# CONTROLSS_ECAP5_CONTROLSS_ECAP5 register map
Vendor: Texas Instruments
Peripheral module from a debugger description file (folder AM263).
Registers are 32-bit, read-write, reset 0x0 unless marked. A register's access mark holds for its fields unless they carry their own. Offsets are as the file gives them; lines under a group give offsets from that group; [hi:lo] are bit positions; {n}, {i} and the like mark numbered series; 'fields as' and 'values as' point back to an identical list; <NAME> marks a mode.

## CONTROLSS_ECAP5_CONTROLSS_ECAP5
0x00 CONTROLSS_ECAP5_TSCTR
  [31:0] TSCTR — Active 32-bit counter register that is used as the capture time-base HR mode : 1) This register reads HRCOUNTER value and is not writable 2) can be reset using CTRFILTRESET 3) Its not synchronized to SYSCLK domain so reads may not be accurate
0x04 CONTROLSS_ECAP5_CTRPHS
  [31:0] CTRPHS — Counter phase value register that can be programmed for phase lag/lead. This register CTRPHS is loaded into TSCTR upon either a SYNCI event or S/W force via a control bit. Used to achieve phase control synchronization with respect to other eCAP and EPWM time-bases. This register is not applicable in HR mode.
0x08 CONTROLSS_ECAP5_CAP1
  [31:0] CAP1 — This register can be loaded (written) by: - Time-Stamp counter value (TSCTR) during a capture event - Software - may be useful for test purposes or initialization - ARPD shadow register (CAP3) when used in APWM mode
0x0C CONTROLSS_ECAP5_CAP2
  [31:0] CAP2 — This register can be loaded (written) by: - Time-Stamp ( counter value) during a capture event - Software - may be useful for test purposes - ACMP shadow register (CAP4) when used in APWM mode
0x10 CONTROLSS_ECAP5_CAP3
  [31:0] CAP3 — In CMP mode, this is a time-stamp capture register. In APWM mode, this is the period shadow (APRD) register. You can update the PWM period value through this register. CAP3 (APRD) shadows CAP1 in this mode.
0x14 CONTROLSS_ECAP5_CAP4
  [31:0] CAP4 — In CMP mode, this is a time-stamp capture register. In APWM mode, this is the compare shadow (ACMP) register. You can update the PWM compare value via this register. CAP4 (ACMP) shadows CAP2 in this mode.
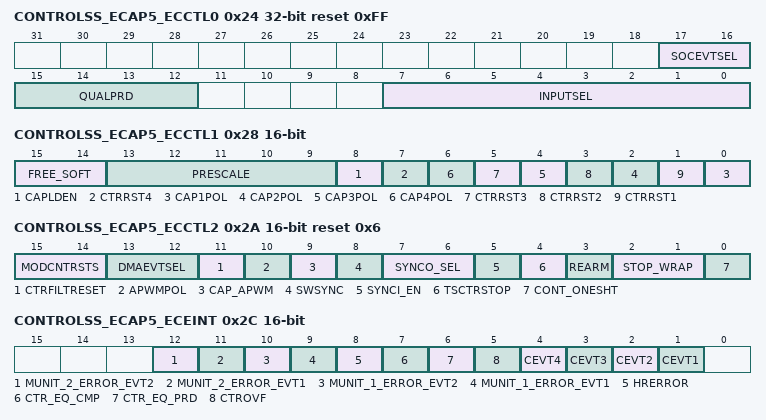
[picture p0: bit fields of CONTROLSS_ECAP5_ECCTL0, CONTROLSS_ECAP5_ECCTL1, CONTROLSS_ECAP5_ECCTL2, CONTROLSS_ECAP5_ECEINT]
0x24 CONTROLSS_ECAP5_ECCTL0 reset 0xFF
  [17:16] SOCEVTSEL — ADC SOC event select Capture Mode: 00b (R/W) = SOC trigger source is CEVT1 01b (R/W) = SOC trigger source is CEVT2 10b (R/W) = SOC trigger source is CEVT3 11b (R/W) = SOC trigger source is CEVT4 APWM Mode: 00b (R/W) = SOC trigger interrupt source is period match 01b (R/W) = SOC trigger interrupt source is compare match 10b (R/W) = SOC trigger interrupt source is period match or compare match 11b (R/W) = Disabled
  [15:12] QUALPRD — Qual period to filter out noise on input signals being monitored, Not applicable for HR mode. 0x0 : Bypass 0x1 : pulses of with 1 cycle or less will be filtered out 0x2 : pulses of with 2 cycles or less will be filtered out .... 0xF : pulses of with 15 cycles or less will be filtered out
  [7:0] INPUTSEL — Capture input source select bits 0x0 capture input is ECAPxINPUT[0] 0x1 capture input is ECAPxINPUT[1] 0x2 capture input is ECAPxINPUT[2] ... 0xFF capture input is ECAPxINPUT[256]
0x28 CONTROLSS_ECAP5_ECCTL1 16-bit
  [15:14] FREE_SOFT — Emulation Control 0x0 | ECAP_STOP_EMUTSCTR counter stops immediately on emulation suspend 0x1 | ECAP_RUNS_UNTILTSCTR counter runs until = 0 0x2 | ECAP_UNAF_EMU_SUSTSCTR counter is unaffected by emulation suspend (Run Free) 0x3 | ECAP_UNAF_EMU_SUS2TSCTR counter is unaffected by emulation suspend (Run Free)
  [13:9] PRESCALE — Event Filter prescale select 0x00 | ECAP_DIV1Divide by 1 (i.e,. no prescale, by-pass the prescaler) 0x01 | ECAP_DIV2Divide by 2 0x02 | ECAP_DIV4Divide by 4 0x03 | ECAP_DIV6Divide by 6 0x04 | ECAP_DIV8Divide by 8 0x05 | ECAP_DIV10Divide by 10 0x1E | ECAP_DIV60Divide by 60 0x1F | ECAP_DIV62Divide by 62
  [8] CAPLDEN — Enable Loading of CAP1-4 registers on a capture event. Note that this bit does not disable CEVTn events from being generated. 0 | ECAP_DISABLEDisable CAP1-4 register loads at capture event time. 1 | ECAP_ENABLEEnable CAP1-4 register loads at capture event time.
  [7] CTRRST4 — Counter Reset on Capture Event 4 0 | ECAP_DO_NOT_RESET_EVENT4Do not reset counter on Capture Event 4 (absolute time stamp operation) 1 | ECAP_RESET_EVENT4Reset counter after Capture Event 4 time-stamp has been captured (used in difference mode operation)
  [2n-2] CAP{n}POL (n=1..4) — Capture Event {n} Polarity select 0 | ECAP_CAP_EVENT{n}_RISECapture Event {n} triggered on a rising edge (RE) 1 | ECAP_CAP_EVENT{n}_FALLCapture Event {n} triggered on a falling edge (FE)
  [5] CTRRST3 — Counter Reset on Capture Event 3 0 | ECAP_DO_NOT_RESET_EVENT3Do not reset counter on Capture Event 3 (absolute time stamp) 1 | ECAP_RESET_EVENT3Reset counter after Event 3 time-stamp has been captured (used in difference mode operation)
  [3] CTRRST2 — Counter Reset on Capture Event 2 0 | ECAP_DO_NOT_RESET_EVENT2Do not reset counter on Capture Event 2 (absolute time stamp) 1 | ECAP_RESET_EVENT2Reset counter after Event 2 time-stamp has been captured (used in difference mode operation)
  [1] CTRRST1 — Counter Reset on Capture Event 1 0 | ECAP_DO_NOT_RESET_EVENT1Do not reset counter on Capture Event 1 (absolute time stamp) 1 | ECAP_RESET_EVENT1Reset counter after Event 1 time-stamp has been captured (used in difference mode operation)
0x2A CONTROLSS_ECAP5_ECCTL2 16-bit access not given reset 0x6
  [15:14] MODCNTRSTS rw — This bit field reads current status on modulo counter 00b (R) = CAP1 register gets loaded on next capture event. 01b (R) = CAP2 register gets loaded on next capture event. 10b (R) = CAP3 register gets loaded on next capture event. 11b (R) = CAP4 register gets loaded on next capture event.
  [13:12] DMAEVTSEL rw — DMA event select Capture Mode: 00b (R/W) = DMA interrupt source is CEVT1 01b (R/W) = DMA interrupt source is CEVT2 10b (R/W) = DMA interrupt source is CEVT3 11b (R/W) = DMA interrupt source is CEVT4 APWM Mode: 00b (R/W) = DMA interrupt source is period match 01b (R/W) = DMA interrupt source is compare match 10b (R/W) = DMA interrupt source is period match or compare match 11b (R/W) = Disabled
  [11] CTRFILTRESET — Reset Bit 0h (R) = No effect 1h (W) = Resets event filter, counter, modulo counter and CEVT[1,2,3,4] and CNTOVF , HRERROR flags Note: This provides an ability start capture module from known state in case spurious inputs are captured while ECAP is configured. (access RW RRETURNS0S)
  [10] APWMPOL rw — APWM output polarity select. This is applicable only in APWM operating mode. 0 | ECAP_OUTPUT_ACTIVE_HIGHOutput is active high (Compare value defines high time) 1 | ECAP_OUTPUT_ACTIVE_LOWOutput is active low (Compare value defines low time)
  [9] CAP_APWM rw — CAP/APWM operating mode select 0 | ECAP_MODULEECAP module operates in capture mode. This mode forces the following configuration: - Inhibits TSCTR resets via CTR = PRD event - Inhibits shadow loads on CAP1 and 2 registers - Permits user to enable CAP1-4 register load - CAPx/APWMx pin operates as a capture input 1 | ECAP_MODULE_APWMECAP module operates in APWM mode. This mode forces the following configuration: - Resets TSCTR on CTR = PRD event (period boundary - Permits shadow loading on CAP1 and 2 registers - Disables loading of time-stamps into CAP1-4 registers - CAPx/APWMx pin operates as a APWM output
  [8] SWSYNC — Software-forced Counter (TSCTR) Synchronizer. This provides the user a method to generate a synchronization pulse through software. In APWM mode, the synchronization pulse can also be sourced from the CTR = PRD event. 0 | ECAP_ZERO_NOEFFECTWriting a zero has no effect. Reading always returns a zero 1 | ECAP_WRITE_TSCTRWriting a one forces a TSCTR shadow load of current ECAP module and any ECAP modules down-stream providing the SYNCO_SEL bits are 0,0. After writing a 1, this bit returns to a zero. Note: Selection CTR = PRD is meaningful only in APWM mode; however, you can choose it in CAP mode if you find doing so useful. (access RW RRETURNS0S)
  [7:6] SYNCO_SEL rw — Sync-Out Select 0x0 | SWSYNCsync out signal is SWSYNC 0x1 | ECAP_CTR_PRD_TO_SYNCOUTSelect CTR = PRD event to be the sync-out signal 0x2 | ECAP_DISABLE_SYNC_OUTDisable sync out signal 0x3 | ECAP_DISABLE_SYNC_OUTDisable sync out signal
  [5] SYNCI_EN rw — Counter (TSCTR) Sync-In select mode 0 | ECAP_DISABLE_SYNC_INDisable sync-in option 1 | ECAP_ENABLE_COUNTER_REGISTEREnable counter (TSCTR) to be loaded from CTRPHS register upon either a SYNCI signal or a S/W force event.
  [4] TSCTRSTOP rw — Time Stamp (TSCTR) Counter Stop (freeze) Control 0 | ECAP_TSCTR_STOPPEDTSCTR stopped 1 | ECAP_TSCTR_FREE_RUNNINGTSCTR free-running
  [3] REARM — Re-Arming Control. Note: The re-arm function is valid in one shot or continuous mode 0 | ECAP_NO_EFFECT_RETURNS_0Has no effect (reading always returns a 0) 1 | ECAP_ARMS_ONESHOTArms the one-shot sequence as follows: 1) Resets the Mod4 counter to zero 2) Unfreezes the Mod4 counter 3) Enables capture register loads (access RW RRETURNS0S)
  [2:1] STOP_WRAP rw — Stop value for one-shot mode. This is the number (between 1-4) of captures allowed to occur before the CAP(1-4) registers are frozen, that is, capture sequence is stopped. Wrap value for continuous mode. This is the number (between 1-4) of the capture register in which the circular buffer wraps around and starts again. Notes: STOP_WRAP is compared to Mod4 counter and, when equal, 2 actions occur: - Mod4 counter is stopped (frozen) - Capture register loads are inhibited In one-shot mode, further interrupt events are blocked until re-armed. 0x0 | ECAP_STOPEVENT1_WRAPEVENT2Stop after Capture Event 1 in one-shot mode Wrap after Capture Event 1 in continuous mode. 0x1 | ECAP_STOPEVENT2_WRAPEVENT2Stop after Capture Event 2 in one-shot mode Wrap after Capture Event 2 in continuous mode. 0x2 | ECAP_STOPEVENT3_WRAPEVENT2Stop after Capture Event 3 in one-shot mode Wrap after Capture Event 3 in continuous mode. 0x3 | ECAP_STOPEVENT4_WRAPEVENT2Stop after Capture Event 4 in one-shot mode Wrap after Capture Event 4 in continuous mode.
  [0] CONT_ONESHT rw — Continuous or one-shot mode control (applicable only in capture mode) 0 | ECAP_OPP_CONTOperate in continuous mode 1 | ECAP_OPP_ONEOperate in one-Shot mode
0x2C CONTROLSS_ECAP5_ECEINT 16-bit
  [12] MUNIT_2_ERROR_EVT2 — Monitoring unit 2 error event 2 interrupt enable 0 : Disable Monitoring unit 2 error event 2 interrupt 1 : Enable Monitoring unit 2 error event 2 interrupt
  [11] MUNIT_2_ERROR_EVT1 — Monitoring unit 2 error event 2 interrupt enable 0 : Disable Monitoring unit 2 error event 1 interrupt 1 : Enable Monitoring unit 2 error event 1 interrupt
  [10] MUNIT_1_ERROR_EVT2 — Monitoring unit 1 error event 1 interrupt enable 0 : Disable Monitoring unit 1 error event 2 interrupt 1 : Enable Monitoring unit 1 error event 2 interrupt
  [9] MUNIT_1_ERROR_EVT1 — Monitoring unit 1 error event 1 interrupt enable 0 : Disable Monitoring unit 1 error event 1 interrupt 1 : Enable Monitoring unit 1 error event 1 interrupt
  [8] HRERROR — High resolution error interrupt enable 0 | ECAP_DISAB_HRERROR_INTERRUPTDisable High Resolution Error as an Interrupt source 1 | ECAP_ENAB_HRERROR_INTERRUPTEnable High Resolution Error as an Interrupt source
  [7] CTR_EQ_CMP — Counter Equal Compare Interrupt Enable 0 | ECAP_DISAB_CE_INTERRUPTDisable Compare Equal as an Interrupt source 1 | ECAP_ENAB_CE_INTERRUPTEnable Compare Equal as an Interrupt source
  [6] CTR_EQ_PRD — Counter Equal Period Interrupt Enable 0 | ECAP_DISAB_PE_INTERRUPTDisable Period Equal as an Interrupt source 1 | ECAP_ENAB_PE_INTERRUPTEnable Period Equal as an Interrupt source
  [5] CTROVF — Counter Overflow Interrupt Enable 0 | ECAP_DISAB_CO_INTERRUPTDisabled counter Overflow as an Interrupt source 1 | ECAP_ENAB_CO_INTERRUPTEnable counter Overflow as an Interrupt source
  [4] CEVT4 — Capture Event 4 Interrupt Enable 0 | ECAP_DISAB_CAP4_INTERRUPTDisable Capture Event 4 as an Interrupt source 1 | ECAP_ENAB_CAP4_INTERRUPTCapture Event 4 Interrupt Enable
  [3] CEVT3 — Capture Event 3 Interrupt Enable 0 | ECAP_DISAB_CAP3_INTERRUPTDisable Capture Event 3 as an Interrupt source 1 | ECAP_ENAB_CAP3_INTERRUPTEnable Capture Event 3 as an Interrupt source
  [2] CEVT2 — Capture Event 2 Interrupt Enable 0 | ECAP_DISAB_CAP2_INTERRUPTDisable Capture Event 2 as an Interrupt source 1 | ECAP_ENAB_CAP2_INTERRUPTEnable Capture Event 2 as an Interrupt source
  [1] CEVT1 — Capture Event 1 Interrupt Enable 0 | ECAP_DISAB_CAP1_INTERRUPTDisable Capture Event 1 as an Interrupt source 1 | ECAP_ENAB_CAP1_INTERRUPTEnable Capture Event 1 as an Interrupt source
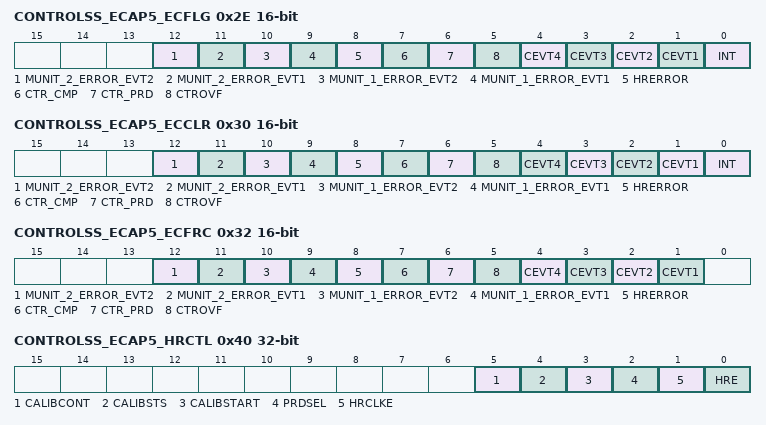
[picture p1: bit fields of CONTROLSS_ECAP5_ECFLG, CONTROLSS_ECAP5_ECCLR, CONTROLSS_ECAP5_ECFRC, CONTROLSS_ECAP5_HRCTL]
0x2E CONTROLSS_ECAP5_ECFLG 16-bit ro
  [12] MUNIT_2_ERROR_EVT2 — Error event 2 Interrupt Flag from monitoring unit 2
  [11] MUNIT_2_ERROR_EVT1 — Error event 2 Interrupt Flag from monitoring unit 2
  [10] MUNIT_1_ERROR_EVT2 — Error event 2 Interrupt Flag from monitoring unit 1
  [9] MUNIT_1_ERROR_EVT1 — Error event 2 Interrupt Flag from monitoring unit 1
  [8] HRERROR — High resolution error status flag Read0 | ECAP_INDICATE_NO_EVENTIndicates no event occurred Read1 | ECAP_INDICATE_HIGH_RESOLUTION_ERRORIndicates the High resolution Error occurred
  [7] CTR_CMP — Compare Equal Compare Status Flag. This flag is active only in APWM mode. Read0 | ECAP_INDICATE_NO_EVENTIndicates no event occurred Read1 | ECAP_INDICATE_COUNTER_COMPARE_REGIndicates the counter (TSCTR) reached the compare register value (ACMP)
  [6] CTR_PRD — Counter Equal Period Status Flag. This flag is only active in APWM mode. Read0 | ECAP_INDICATE_NO_EVENTIndicates no event occurred Read1 | ECAP_INDICATE_PERIOD_VALUE_RESETIndicates the counter (TSCTR) reached the period register value (APRD) and was reset.
  [5] CTROVF — Counter Overflow Status Flag. This flag is active in CAP and APWM mode. Read0 | ECAP_INDICATE_NO_EVENTIndicates no event occurred Read1 | ECAP_INDICATE_COUNTER_TRANSIndicates the counter (TSCTR) has made the transition from FFFFFFFF to 00000000
  [4] CEVT4 — Capture Event 4 Status Flag This flag is only active in CAP mode. Read0 | ECAP_INDICATE_NO_EVENTIndicates no event occurred Read1 | ECAP_INDICATE_4TH_EVENT_ECAPXIndicates the fourth event occurred at ECAPx pin
  [3] CEVT3 — Capture Event 3 Status Flag. This flag is active only in CAP mode. Read0 | ECAP_INDICATE_NO_EVENTIndicates no event occurred Read1 | ECAP_INDICATE_3RD_EVENT_ECAPXIndicates the third event occurred at ECAPx pin.
  [2] CEVT2 — Capture Event 2 Status Flag. This flag is only active in CAP mode. Read0 | ECAP_INDICATE_NO_EVENTIndicates no event occurred Read1 | ECAP_INDICATE_2ND_EVENT_ECAPXIndicates the second event occurred at ECAPx pin.
  [1] CEVT1 — Capture Event 1 Status Flag. This flag is only active in CAP mode. Read0 | ECAP_INDICATE_NO_EVENTIndicates no event occurred Read1 | ECAP_INDICATE_1ST_EVENT_ECAPXIndicates the first event occurred at ECAPx pin.
  [0] INT — Global Interrupt Status Flag Read0 | ECAP_INDICATE_NO_EVENTIndicates no event occurred Read1 | ECAP_INDICATE_INTERRUPTIndicates that an interrupt was generated.
0x30 CONTROLSS_ECAP5_ECCLR 16-bit access not given
  [12] MUNIT_2_ERROR_EVT2 — Writing '1' clears MUNIT_2_ERROR_EVT2 interrupt flag (access RW RRETURNS0S)
  [11] MUNIT_2_ERROR_EVT1 — Writing '1' clears MUNIT_2_ERROR_EVT1 interrupt flag (access RW RRETURNS0S)
  [10] MUNIT_1_ERROR_EVT2 — Writing '1' clears MUNIT_1_ERROR_EVT2 interrupt flag (access RW RRETURNS0S)
  [9] MUNIT_1_ERROR_EVT1 — Writing '1' clears MUNIT_1_ERROR_EVT1 interrupt flag (access RW RRETURNS0S)
  [8] HRERROR — High resolution error status Clear 0 | ECAP_0_NO_EFFECTWriting a 0 has no effect. Always reads back a 0 1 | ECAP_1_CLEARS_HRERRORWriting a 1 clears the HRERROR flag. (access RW RRETURNS0S)
  [7] CTR_CMP — Counter Equal Compare Status Clear 0 | ECAP_0_NO_EFFECTWriting a 0 has no effect. Always reads back a 0 1 | ECAP_1_CLEARS_CTR_CMPWriting a 1 clears the CTR=CMP flag. (access RW RRETURNS0S)
  [6] CTR_PRD — Counter Equal Period Status Clear 0 | ECAP_0_NO_EFFECTWriting a 0 has no effect. Always reads back a 0 1 | ECAP_1_CLEARS_CTR_PRDWriting a 1 clears the CTR=PRD flag. (access RW RRETURNS0S)
  [5] CTROVF — Counter Overflow Status Clear 0 | ECAP_0_NO_EFFECTWriting a 0 has no effect. Always reads back a 0 1 | ECAP_1_CLEARS_CTROVFWriting a 1 clears the CTROVF flag. (access RW RRETURNS0S)
  [n] CEVT{n} (n=1..4) — Capture Event {n} Status Clear 0 | ECAP_0_NO_EFFECTWriting a 0 has no effect. Always reads back a 0 1 | ECAP_1_CLEARS_CEVT{n}Writing a 1 clears the CEVT{n} flag. (access RW RRETURNS0S)
  [0] INT — ECAP Global Interrupt Status Clear 0 | ECAP_0_NO_EFFECTWriting a 0 has no effect. Always reads back a 0 1 | ECAP_1_CLEARS_INTWriting a 1 clears the INT flag and enable further interrupts to be generated if any of the event flags are set to 1 (access RW RRETURNS0S)
0x32 CONTROLSS_ECAP5_ECFRC 16-bit access not given
  [12] MUNIT_2_ERROR_EVT2 — Writing '1' sets MUNIT_2_ERROR_EVT2 interrupt flag (access RW RRETURNS0S)
  [11] MUNIT_2_ERROR_EVT1 — Writing '1' sets MUNIT_2_ERROR_EVT1 interrupt flag (access RW RRETURNS0S)
  [10] MUNIT_1_ERROR_EVT2 — Writing '1' sets MUNIT_1_ERROR_EVT2 interrupt flag (access RW RRETURNS0S)
  [9] MUNIT_1_ERROR_EVT1 — Writing '1' sets MUNIT_1_ERROR_EVT1 interrupt flag (access RW RRETURNS0S)
  [8] HRERROR — High resolution error Force interrupt 0 | ECAP_NO_EFFECT_0No effect. Always reads back a 0. 1 | ECAP_1_SETS_CTR_CMPWriting a 1 sets the CTR_CMP flag. (access RW RRETURNS0S)
  [7] CTR_CMP — Force Counter Equal Compare Interrupt. This event is only active in APWM mode. 0 | ECAP_NO_EFFECT_0No effect. Always reads back a 0. 1 | ECAP_1_SETS_CTR_CMPWriting a 1 sets the CTR_CMP flag. (access RW RRETURNS0S)
  [6] CTR_PRD — Force Counter Equal Period Interrupt. This event is only active in APWM mode. 0 | ECAP_NO_EFFECT_0No effect. Always reads back a 0. 1 | ECAP_1_CLEARS_CTR_PRDWriting a 1 sets the CTR_PRD flag. (access RW RRETURNS0S)
  [5] CTROVF — Force Counter Overflow 0 | ECAP_NO_EFFECT_0No effect. Always reads back a 0. 1 | ECAP_1_SETS_CTROVFWriting a 1 to this bit sets the CTROVF flag. (access RW RRETURNS0S)
  [4] CEVT4 — Force Capture Event 4. This event is only active in CAP mode. 0 | ECAP_NO_EFFECT_0No effect. Always reads back a 0. 1 | ECAP_1_SETS_CEVT4Writing a 1 sets the CEVT4 flag. (access RW RRETURNS0S)
  [3] CEVT3 — Force Capture Event 3. This event is only active in CAP mode. 0 | ECAP_NO_EFFECT_0No effect. Always reads back a 0. 1 | ECAP_1_SETS_CEVT3Writing a 1 sets the CEVT3 flag. (access RW RRETURNS0S)
  [2] CEVT2 — Force Capture Event 2. This event is only active in CAP mode. 0 | ECAP_NO_EFFECT_0No effect. Always reads back a 0. 1 | ECAP_1_SETS_CEVT2Writing a 1 sets the CEVT2 flag. (access RW RRETURNS0S)
  [1] CEVT1 — Force Capture Event 1. This event is only active in CAP mode. 0 | ECAP_NO_EFFECT_0No effect. Always reads back a 0. 1 | ECAP_1_SETS_CEVT1Sets the CEVT1 flag. (access RW RRETURNS0S)
0x3C CONTROLSS_ECAP5_ECAPSYNCINSEL reset 0x1
  [6:0] SEL — These bits determines the source of SYNCIN signal. 0x0 : Disabled using SOC tieoff. 0x7F : Refer to SOC spec for details.
0x40 CONTROLSS_ECAP5_HRCTL access not given
  [5] CALIBCONT rw — Continuous mode Calibration Select Bit: 0 Continuous mode disabled. 1 Continuous mode enabled. Calibration automatically restarts at end of current calibration cycle.
  [4] CALIBSTS ro — Calibration status Bit: 0 No active calibration cycle 1 Calibration cycle in progress
  [3] CALIBSTART — Calibration start Bit: 0 No effect 1 Starts the calibration cycle (access RW RRETURNS0S)
  [2] PRDSEL rw — Calibration Period Match Select Bit: 0 Use SYSCLK Counter For Period Match (default at reset) 1 Reserved
  [1] HRCLKE rw — High Resolution Clock Enable Bit: 0 High resolution clock disabled (default at reset) 1 High resolution clock enabled. The clock should be enabled before enabling the high res function via the HRE bit.
  [0] HRE rw — High Resolution Enable Bit: 0 High resolution mode disabled (default at reset) 1 High resolution mode enabled. Enabling this mode will connect the capture registers and edge event modes of the ECAP to be accessed by the High Res function. Note: The High Res clock needs to be enabled (using the HRCLKE bit) first before enabling the module. Allow a certain start up stabilization period before enabling the module.
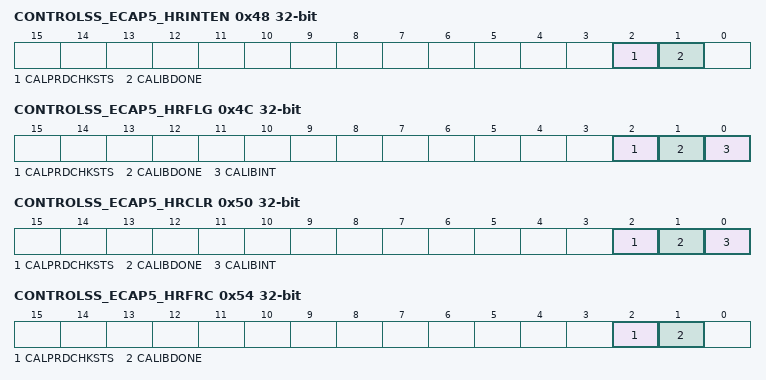
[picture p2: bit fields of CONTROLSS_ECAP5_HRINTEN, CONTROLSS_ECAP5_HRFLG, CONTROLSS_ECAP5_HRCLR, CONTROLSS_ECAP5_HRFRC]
0x48 CONTROLSS_ECAP5_HRINTEN
  [2] CALPRDCHKSTS — Calibration Period Check status Interrupt Enable: 0 Disable Calibration Period Check interrupt status 1 Enable Calibration Period Check interrupt status
  [1] CALIBDONE — Calibration done Interrupt Enable: 0 Disable Calibration done Interrupt 1 Enable Calibration done Interrupt
0x4C CONTROLSS_ECAP5_HRFLG ro
  [2] CALPRDCHKSTS — Calibration period check status Flag Bit: 1 Indicates that calibration ended before PRDCHK due to overflow on one of the counters. 0 Indicates no event occurred. Note: This bit remains latched until cleared by the user using the HRCLR [CALPRDCHKSTS] bit.
  [1] CALIBDONE — Calibration Done Interrupt Flag Bit: 1 Indicates calibration cycle is completed 0 Indicates calibration cycle has not completed. Note: This bit remains latched until cleared by the user using the HRCLR [CALIBDONE] bit.
  [0] CALIBINT — Global calibration Interrupt Status Flag: 1 Indicates that an interrupt was generated from CALIBDONE or CALPRDCHKSTS. 0 Indicates no interrupt generated.
0x50 CONTROLSS_ECAP5_HRCLR access not given
  [2] CALPRDCHKSTS — Clear Calibration period check status Flag Bit: 1 Clears the CALPRDCHKSTS flag register bit. 0 No effect. Note: H/W has priority over CPU writes if the user tries to clear a flag bit and an event occurs on the same cycle that tries to set the flag for the selected bit. (access RW RRETURNS0S)
  [1] CALIBDONE — Clear Calibration Done Interrupt Flag Bit: 1 Clears the CALIBDONE interrupt flag register bit. 0 No effect. Note: H/W has priority over CPU writes if the user tries to clear a flag bit and an event occurs on the same cycle that tries to set the flag for the selected bit. (access RW RRETURNS0S)
  [0] CALIBINT — Clear Global calibration Interrupt Flag 1 Clears the Global interrupt flag and enables further interrupts to be generated if any of the event flags are set. 0 No effect. (access RW RRETURNS0S)
0x54 CONTROLSS_ECAP5_HRFRC access not given
  [2] CALPRDCHKSTS — Force CALPRDCHKSTS flag: 0 No effect 1 Sets the CALPRDCHKSTS flag. (access RW RRETURNS0S)
  [1] CALIBDONE — Force CALIBDONE flag: 0 No effect 1 Sets the CALIBDONE flag. (access RW RRETURNS0S)
0x58 CONTROLSS_ECAP5_HRCALPRD reset 0x3FFFFF
  [31:0] PRD — Register to program calibration period. The period value is matched against HRSYSCLKCTR. On a match an interrupt is generated and the counter registers values are captured.
0x5C CONTROLSS_ECAP5_HRSYSCLKCTR ro
  [31:0] HRSYSCLKCTR — Current SYSCLK counter value
0x60 CONTROLSS_ECAP5_HRSYSCLKCAP ro
  [31:0] HRSYSCLKCAP — HRSYSCLKCTR is captures into this register at end of calibration cycle.
0x64 CONTROLSS_ECAP5_HRCLKCTR ro
  [31:0] HRCLKCTR — Current HRCLK counter value Note: HRCLK is not synchronized to SYSCLK domain so reads may not be accurate
0x68 CONTROLSS_ECAP5_HRCLKCAP ro
  [31:0] HRCLKCAP — HRCLKCTR is captures into this register at end of calibration cycle. Note: HRCLK is not synchronized to SYSCLK domain so reads may not be accurate
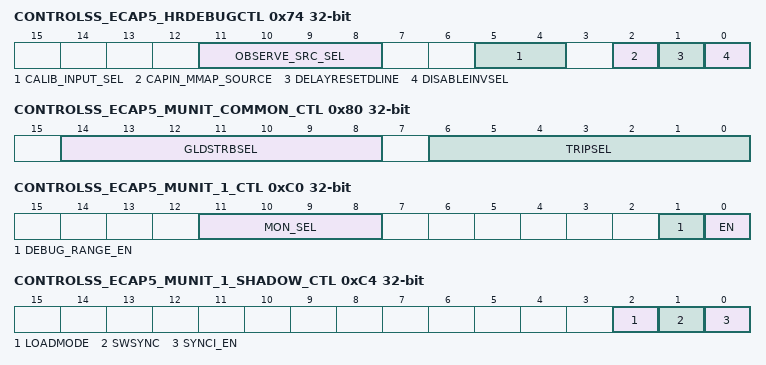
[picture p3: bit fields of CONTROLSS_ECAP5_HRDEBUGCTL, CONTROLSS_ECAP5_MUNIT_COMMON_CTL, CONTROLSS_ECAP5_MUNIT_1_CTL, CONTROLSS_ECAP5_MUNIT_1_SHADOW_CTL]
0x74 CONTROLSS_ECAP5_HRDEBUGCTL
  [11:8] OBSERVE_SRC_SEL — Select bits for selecting source for OBSERVE1 and OBSERVE2 registers 1000 HROUTH and HROUTL will read HR1OUT 1001 HROUTH and HROUTL will read HR2OUT 1010 HROUTH and HROUTL will read Capture Delayline 1 OBS1 1011 HROUTH and HROUTL will read Capture Delayline 2 OBS1 1100 HROUTH and HROUTL will read Capture Delayline 1 OBS2 1101 HROUTH and HROUTL will read Capture Delayline 2 OBS2
  [5:4] CALIB_INPUT_SEL — Select bit for calibration input, can be used to get fault coverage using these inputs 00 CAPIN is one of 128 inputs selected by INPUTSEL 01 CAPIN is connected to CAPIN_MEMMAP_SOURCE 10 CAPIN is internally generated signal waveform with 8*HRCLK cycle high and 8*HRCLK cycle low, used for linearity check of capture delay line 1 11 CAPIN is internally generated signal waveform with 8*HRCLK cycle high and 8*HRCLK cycle low, delayed by half HRCLK, used for linearity check of capture delay line 2
  [2] CAPIN_MMAP_SOURCE — Memory mapped CAPIN source Note : select CALIN source first, it may happen that you may see interrupt if MMAP source is different from current value of CAPIN. This is debug feature hence no additional HW is necessary to prevent this.
  [1] DELAYRESETDLINE — Controls the reset delayline timing 0 reset is forced on next falling edge of HRCLK (1/2 cycle after capture) 1 reset is applied a cycle later (1 1/2 cycles after capture)
  [0] DISABLEINVSEL — Disable INVSEL Logic: 0 State machine controls inversion on input signal 1 CAPIN signal propagated into delay line without inversion, this means only rising edges can be measured
0x78 CONTROLSS_ECAP5_HRDEBUGOBSERVE1 ro
  [31:0] HROUTH — Reads raw output of HROUT capture delay line 1
0x7C CONTROLSS_ECAP5_HRDEBUGOBSERVE2 ro
  [31:0] HROUTL — Reads raw output of HROUT capture delay line 2
0x80 CONTROLSS_ECAP5_MUNIT_COMMON_CTL
  [14:8] GLDSTRBSEL — Global load strobe select to enable shadow to active loading 0x0 : Disabled with SOC level tieoff. 0x1 to 0x7F : Global load strobe from SOC level including ETPWM global load strobes.
  [6:0] TRIPSEL — Trip signal select to disable and enable signal monitoring automatically 0x0 : Disabled, Trip signals does not affect signal monitoring, achieved with SOC level tieoff. 0x1 to 0x7F : Signal monioring is disabled when selected signal is high and enabled when it is low
0xC0 CONTROLSS_ECAP5_MUNIT_1_CTL
  [11:8] MON_SEL — Type of monitoring 0 : High Pulse width 1 : Low Pulse width 2 : Period width from Rise to Rise 3 : Period width from fall to fall 4 : Monitor rise edge 5 : Monitor fall edge 6-15 : Reserved (High Pulse width)
  [1] DEBUG_RANGE_EN — Debug mode enable. 0 : Debug mode is disabled. 1 : Debug mode of monitoring unit 1 is enabled to obtain the variation seen in the system for debug purpose. Range is captured in MUNIT_1_DEBUG_RANGE_MIN and MUNIT_1_DEBUG_RANGE_MAX registers Toggle DEBUG_RANGE_EN to restart this process, this will initialize MUNIT_1_DEBUG_RANGE_MIN and MUNIT_1_DEBUG_RANGE_MAX registers.
  [0] EN — 0 : Monitoring unit 1 is disabled 1 : Monitoring unit 1 is enabled
0xC4 CONTROLSS_ECAP5_MUNIT_1_SHADOW_CTL access not given
  [2] LOADMODE rw — Load mode 0 : Active registers are loaded with shadow on next sync event 1 : Active registers are loaded with shadow on EPWMx.GLDLCSTRB event
  [1] SWSYNC — Copies Min and Max values from shadow to active registers immediately if MUNIT_1_SHADOW_CTL.SYNCI_EN is set. (access RW RRETURNS0S)
  [0] SYNCI_EN rw — Shadow Enable 0 : Disabled 1 : Enabled
0xD0 CONTROLSS_ECAP5_MUNIT_1_MIN
  [31:0] MIN_VALUE — Minimum value for monitoring
0xD4 CONTROLSS_ECAP5_MUNIT_1_MAX
  [31:0] MAX_VALUE — Maximum value for monitoring
0xD8 CONTROLSS_ECAP5_MUNIT_1_MIN_SHADOW
  [31:0] MIN_VALUE_SHADOW — Shadow minimum value for monitoring. Shadow value is loaded to active register on Sync event or global load strobe.
0xDC CONTROLSS_ECAP5_MUNIT_1_MAX_SHADOW
  [31:0] MAX_VALUE_SHADOW — Shadow maximum value for monitoring. Shadow value is loaded to active register on Sync event or global load strobe.
0xE0 CONTROLSS_ECAP5_MUNIT_1_DEBUG_RANGE_MIN ro reset 0xFFFFFFFF
  [31:0] MIN_VALUE — Observed Min value of check being enabled on minotoring unit 1. Is updated when MUNIT_1_CTL.DEBUG_RANGE_EN is set to '1'
0xE4 CONTROLSS_ECAP5_MUNIT_1_DEBUG_RANGE_MAX ro
  [31:0] MAX_VALUE — Observed Min value of check being enabled on minotoring unit 1. Is updated when MUNIT_1_CTL.DEBUG_RANGE_EN is set to '1'
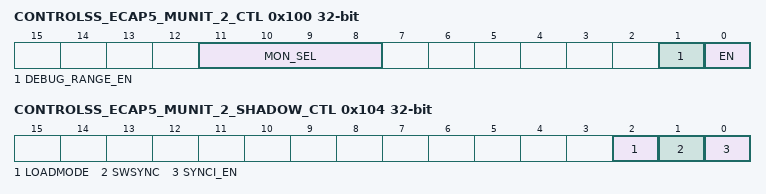
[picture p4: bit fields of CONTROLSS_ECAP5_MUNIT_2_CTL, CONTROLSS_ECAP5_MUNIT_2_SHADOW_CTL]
0x100 CONTROLSS_ECAP5_MUNIT_2_CTL
  [11:8] MON_SEL — Type of monitoring 0 : High Pulse width 1 : Low Pulse width 2 : Period width from Rise to Rise 3 : Period width from fall to fall 4 : Monitor rise edge 5 : Monitor fall edge 6-15 : Reserved (High Pulse width)
  [1] DEBUG_RANGE_EN — Debug mode enable. 0 : Debug mode is disabled. 1 : Debug mode of monitoring unit 2 is enabled to obtain the variation seen in the system for debug purpose. Range is captured in MUNIT_2_DEBUG_RANGE_MIN and MUNIT_2_DEBUG_RANGE_MAX registers Toggle DEBUG_RANGE_EN to restart this process, this will initialize MUNIT_2_DEBUG_RANGE_MIN and MUNIT_2_DEBUG_RANGE_MAX registers.
  [0] EN — 0 : Monitoring unit 2 is disabled 1 : Monitoring unit 2 is enabled
0x104 CONTROLSS_ECAP5_MUNIT_2_SHADOW_CTL access not given
  [2] LOADMODE rw — Load mode 0 : Active registers are loaded with shadow on next sync event 1 : Active registers are loaded with shadow on EPWMx.GLDLCSTRB event
  [1] SWSYNC — Copies Min and Max values from shadow to active registers immediately if MUNIT_2_SHADOW_CTL.SYNCI_EN is set. (access RW RRETURNS0S)
  [0] SYNCI_EN rw — Shadow Enable 0 : Disabled 1 : Enabled
0x110 CONTROLSS_ECAP5_MUNIT_2_MIN
  [31:0] MIN_VALUE — Minimum value for monitoring
0x114 CONTROLSS_ECAP5_MUNIT_2_MAX
  [31:0] MAX_VALUE — Maximum value for monitoring
0x118 CONTROLSS_ECAP5_MUNIT_2_MIN_SHADOW
  fields as CONTROLSS_ECAP5_MUNIT_1_MIN_SHADOW
0x11C CONTROLSS_ECAP5_MUNIT_2_MAX_SHADOW
  fields as CONTROLSS_ECAP5_MUNIT_1_MAX_SHADOW
0x120 CONTROLSS_ECAP5_MUNIT_2_DEBUG_RANGE_MIN ro reset 0xFFFFFFFF
  [31:0] MIN_VALUE — Observed Min value of check being enabled on minotoring unit 2. Is updated when MUNIT_2_CTL.DEBUG_RANGE_EN is set to '1'
0x124 CONTROLSS_ECAP5_MUNIT_2_DEBUG_RANGE_MAX ro
  [31:0] MAX_VALUE — Observed Min value of check being enabled on minotoring unit 2. Is updated when MUNIT_2_CTL.DEBUG_RANGE_EN is set to '1'
